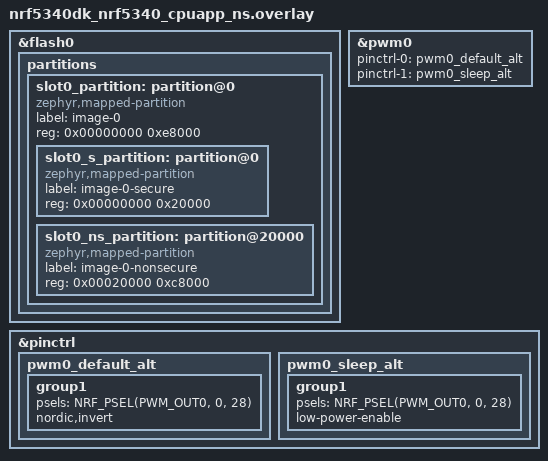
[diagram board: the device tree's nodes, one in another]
/*
 * Copyright (c) 2026 Nordic Semiconductor ASA
 *
 * SPDX-License-Identifier: LicenseRef-Nordic-5-Clause
 */

/* Rebalance secure/non-secure subpartitions to fit larger mesh sample image.
 * MCUboot is removed; slot0 starts at 0x0 and spans 928 KB (0xe8000).
 * Secure: 128 KB, Non-secure: 800 KB.
 */

/delete-node/ &boot_partition;
/delete-node/ &slot0_partition;

&flash0 {
	partitions {
		slot0_partition: partition@0 {
			compatible = "zephyr,mapped-partition";
			label = "image-0";
			reg = <0x00000000 0xe8000>;
			ranges = <0x0 0x0 0xe8000>;
			#address-cells = <1>;
			#size-cells = <1>;

			slot0_s_partition: partition@0 {
				compatible = "zephyr,mapped-partition";
				label = "image-0-secure";
				reg = <0x00000000 0x20000>;
			};

			slot0_ns_partition: partition@20000 {
				compatible = "zephyr,mapped-partition";
				label = "image-0-nonsecure";
				reg = <0x00020000 0xc8000>;
			};
		};
	};
};

&pwm0 {
	status = "okay";
	pinctrl-0 = <&pwm0_default_alt>;
	pinctrl-1 = <&pwm0_sleep_alt>;
	pinctrl-names = "default", "sleep";
};

&pinctrl {
	pwm0_default_alt: pwm0_default_alt {
		group1 {
			psels = <NRF_PSEL(PWM_OUT0, 0, 28)>;
			nordic,invert;
		};
	};

	pwm0_sleep_alt: pwm0_sleep_alt {
		group1 {
			psels = <NRF_PSEL(PWM_OUT0, 0, 28)>;
			low-power-enable;
		};
	};
};
